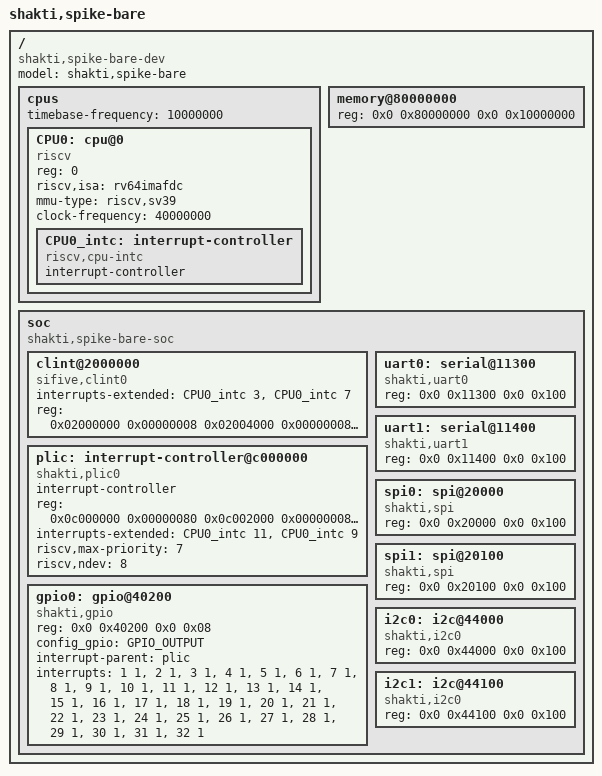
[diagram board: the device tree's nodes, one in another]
#include <zephyr/dt-bindings/gpio/gpio.h>

/ {
  #address-cells = <2>;
  #size-cells = <2>;
  compatible = "shakti,spike-bare-dev";
  model = "shakti,spike-bare";
  cpus {
    #address-cells = <1>;
    #size-cells = <0>;
    timebase-frequency = <10000000>;
      CPU0: cpu@0 {
        device_type = "cpu";
        reg = <0>;
        status = "okay";
        compatible = "riscv";
        riscv,isa = "rv64imafdc";
        mmu-type = "riscv,sv39";
        clock-frequency = <40000000>;
          CPU0_intc: interrupt-controller {
             #address-cells = <0>;
	           #interrupt-cells = <1>;
             interrupt-controller;
             compatible = "riscv,cpu-intc";
          };
      };
  };

  memory@80000000 {
    device_type = "memory";
    reg = <0x0 0x80000000 0x0 0x10000000 >;
  };

  soc {
    #address-cells = <1>;
		#size-cells = <1>;
    compatible = "shakti,spike-bare-soc", "simple-bus";
    ranges;

    clint@2000000 {
      #address-cells = <0>;
      #size-cells = <2>;
      compatible = "sifive,clint0";
      interrupts-extended = <&CPU0_intc 3 &CPU0_intc 7 >;
      reg = <0x02000000 0x00000008
            0x02004000 0x00000008
	    0x0200bff8 0x00000008>;
    };

    plic: interrupt-controller@c000000 {
      #address-cells = <0>;
			#interrupt-cells = <2>;
      compatible = "shakti,plic0";
      interrupt-controller;
      reg = <0x0c000000 0x00000080
			       0x0c002000 0x00000008
			       0x0c200000 0x00001000>;
			reg-names = "prio", "irq_en", "reg";
      interrupts-extended = <&CPU0_intc 11 &CPU0_intc 9>; //11 as to mention MACHINE MODE for CPU or 9 for SUPERVISOR MODE for CPU...
      riscv,max-priority = <7>;
      riscv,ndev = <8>;
    };

    uart0: serial@11300 {
        compatible = "shakti,uart0";
        reg= < 0x0 0x11300 0x0 0x100>;
    };

    uart1: serial@11400 {
        compatible = "shakti,uart1";
        reg= < 0x0 0x11400 0x0 0x100>;
    };    

    spi0: spi@20000 {
            #address-cells = <1>;
            #size-cells = <0>;
            compatible = "shakti,spi";
            reg = <0x0 0x20000 0x0 0x100>;
    };

    spi1: spi@20100 {
           #address-cells = <1>;
			     #size-cells = <0>;
           compatible = "shakti,spi";
           reg = <0x0 0x20100 0x0 0x100>;
    };

    gpio0: gpio@40200 {
                #gpio-cells = <0x2>;
                compatible = "shakti,gpio";
                reg = < 0x0 0x40200 0x0 0x08>;
                config_gpio = <GPIO_OUTPUT>;
                interrupt-parent = <&plic>;
                interrupts = <1 1>, <2 1>, <3 1>, <4 1>,
                          <5 1>, <6 1>, <7 1>, <8 1>,
                          <9 1>, <10 1>, <11 1>, <12 1>,
                          <13 1>, <14 1>, <15 1>, <16 1>,
                          <17 1>, <18 1>, <19 1>, <20 1>,
                          <21 1>, <22 1>, <23 1>, <24 1>,
                          <25 1>, <26 1>, <27 1>, <28 1>,
                          <29 1>, <30 1>, <31 1>, <32 1>;

    };
    
    i2c0: i2c@44000 {
           compatible = "shakti,i2c0";
           reg= <0x0 0x44000 0x0 0x100>;
    };
    i2c1: i2c@44100 {
      compatible = "shakti,i2c0";
      reg= <0x0 0x44100 0x0 0x100>;
    };

  };
};
